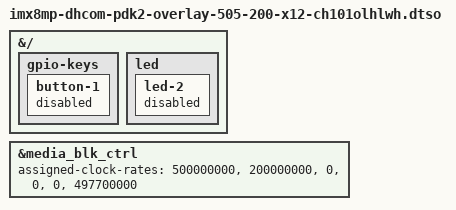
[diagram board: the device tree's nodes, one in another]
// SPDX-License-Identifier: (GPL-2.0+ OR MIT)
/*
 * Copyright (C) 2022-2026 Marek Vasut
 */
/dts-v1/;
/plugin/;

#define DH_OVERLAY_PANEL_I2C_BUS			i2c5
#define DH_OVERLAY_PANEL_I2C_TOUCHSCREEN_PINCTRL	&pinctrl_dhcom_b &pinctrl_dhcom_h
#define DH_OVERLAY_PANEL_I2C_TOUCHSCREEN_IRQ_PARENT	gpio1
#define DH_OVERLAY_PANEL_I2C_TOUCHSCREEN_IRQ_PIN	11
#define DH_OVERLAY_PANEL_I2C_TOUCHSCREEN_RESET_GPIO	gpio1
#define DH_OVERLAY_PANEL_I2C_TOUCHSCREEN_RESET_PIN	8

#include "imx8mp-dhcom-overlay-panel-lvds.dtsi"
#include "imx8mp-dhcom-overlay-panel-ch101olhlwh.dtsi"

&{/} {
	gpio-keys {
		button-1 {
			/* BUTTON1 GPIO conflicts with Touchscreen RESET GPIO-B */
			status = "disabled";
		};
	};

	led {
		led-2 {
			/* LED7 GPIO conflicts with Touchscreen IRQ GPIO-H */
			status = "disabled";
		};
	};
};

&media_blk_ctrl {
	/*
	 * The Chefree CH101OLHLWH-002 panel requires 71.1 MHz LVDS clock.
	 * Set IMX8MP_VIDEO_PLL1 to 497.7 MHz , since 497.7 MHz / 7 = 71.1 MHz .
	 */
	assigned-clock-rates = <500000000>, <200000000>, <0>, <0>, <0>, <497700000>;
};
